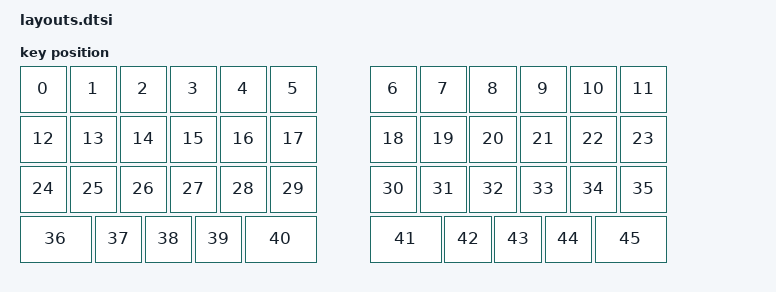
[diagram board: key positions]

#include <physical_layouts.dtsi>
/ {
    physical_layout0: physical_layout0 {
        compatible = "zmk,physical-layout";
        display-name = "Layout";
        keys
            = <&key_physical_attrs 100 100 (-50) 0 0 0 0>
			,<&key_physical_attrs 100 100 50 0 0 0 0>
			,<&key_physical_attrs 100 100 150 0 0 0 0>
			,<&key_physical_attrs 100 100 250 0 0 0 0>
			,<&key_physical_attrs 100 100 350 0 0 0 0>
			,<&key_physical_attrs 100 100 450 0 0 0 0>
			,<&key_physical_attrs 100 100 650 0 0 0 0>
			,<&key_physical_attrs 100 100 750 0 0 0 0>
			,<&key_physical_attrs 100 100 850 0 0 0 0>
			,<&key_physical_attrs 100 100 950 0 0 0 0>
			,<&key_physical_attrs 100 100 1050 0 0 0 0>
			,<&key_physical_attrs 100 100 1150 0 0 0 0>
			,<&key_physical_attrs 100 100 (-50) 100 0 0 0>
			,<&key_physical_attrs 100 100 50 100 0 0 0>
			,<&key_physical_attrs 100 100 150 100 0 0 0>
			,<&key_physical_attrs 100 100 250 100 0 0 0>
			,<&key_physical_attrs 100 100 350 100 0 0 0>
			,<&key_physical_attrs 100 100 450 100 0 0 0>
			,<&key_physical_attrs 100 100 650 100 0 0 0>
			,<&key_physical_attrs 100 100 750 100 0 0 0>
			,<&key_physical_attrs 100 100 850 100 0 0 0>
			,<&key_physical_attrs 100 100 950 100 0 0 0>
			,<&key_physical_attrs 100 100 1050 100 0 0 0>
			,<&key_physical_attrs 100 100 1150 100 0 0 0>
			,<&key_physical_attrs 100 100 (-50) 200 0 0 0>
			,<&key_physical_attrs 100 100 50 200 0 0 0>
			,<&key_physical_attrs 100 100 150 200 0 0 0>
			,<&key_physical_attrs 100 100 250 200 0 0 0>
			,<&key_physical_attrs 100 100 350 200 0 0 0>
			,<&key_physical_attrs 100 100 450 200 0 0 0>
			,<&key_physical_attrs 100 100 650 200 0 0 0>
			,<&key_physical_attrs 100 100 750 200 0 0 0>
			,<&key_physical_attrs 100 100 850 200 0 0 0>
			,<&key_physical_attrs 100 100 950 200 0 0 0>
			,<&key_physical_attrs 100 100 1050 200 0 0 0>
			,<&key_physical_attrs 100 100 1150 200 0 0 0>
			,<&key_physical_attrs 150 100 (-50) 300 0 0 0>
			,<&key_physical_attrs 100 100 100 300 0 0 0>
			,<&key_physical_attrs 100 100 200 300 0 0 0>
			,<&key_physical_attrs 100 100 300 300 0 0 0>
			,<&key_physical_attrs 150 100 400 300 0 0 0>
			,<&key_physical_attrs 150 100 650 300 0 0 0>
			,<&key_physical_attrs 100 100 800 300 0 0 0>
			,<&key_physical_attrs 100 100 900 300 0 0 0>
			,<&key_physical_attrs 100 100 1000 300 0 0 0>
			,<&key_physical_attrs 150 100 1100 300 0 0 0>
            ;
    };
};
    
